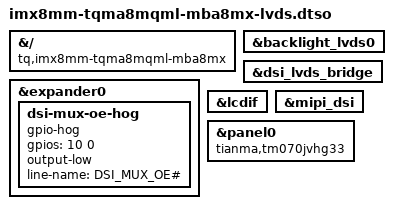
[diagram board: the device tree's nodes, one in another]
// SPDX-License-Identifier: (GPL-2.0-or-later OR MIT)
/*
 * Copyright (c) 2022-23 TQ-Systems GmbH <linux@ew.tq-group.com>,
 * D-82229 Seefeld, Germany.
 * Author: Alexander Stein
 */

/dts-v1/;
/plugin/;

&{/} {
	compatible = "tq,imx8mm-tqma8mqml-mba8mx", "tq,imx8mm-tqma8mqml", "fsl,imx8mm";
};

&backlight_lvds0 {
	status = "okay";
};

&dsi_lvds_bridge {
	status = "okay";
};

&expander0 {
	dsi-mux-oe-hog {
		gpio-hog;
		gpios = <10 0>;
		output-low;
		line-name = "DSI_MUX_OE#";
	};
};

&lcdif {
	status = "okay";
};

&mipi_dsi {
	status = "okay";
};

&panel0 {
	compatible = "tianma,tm070jvhg33";
	status = "okay";
};
